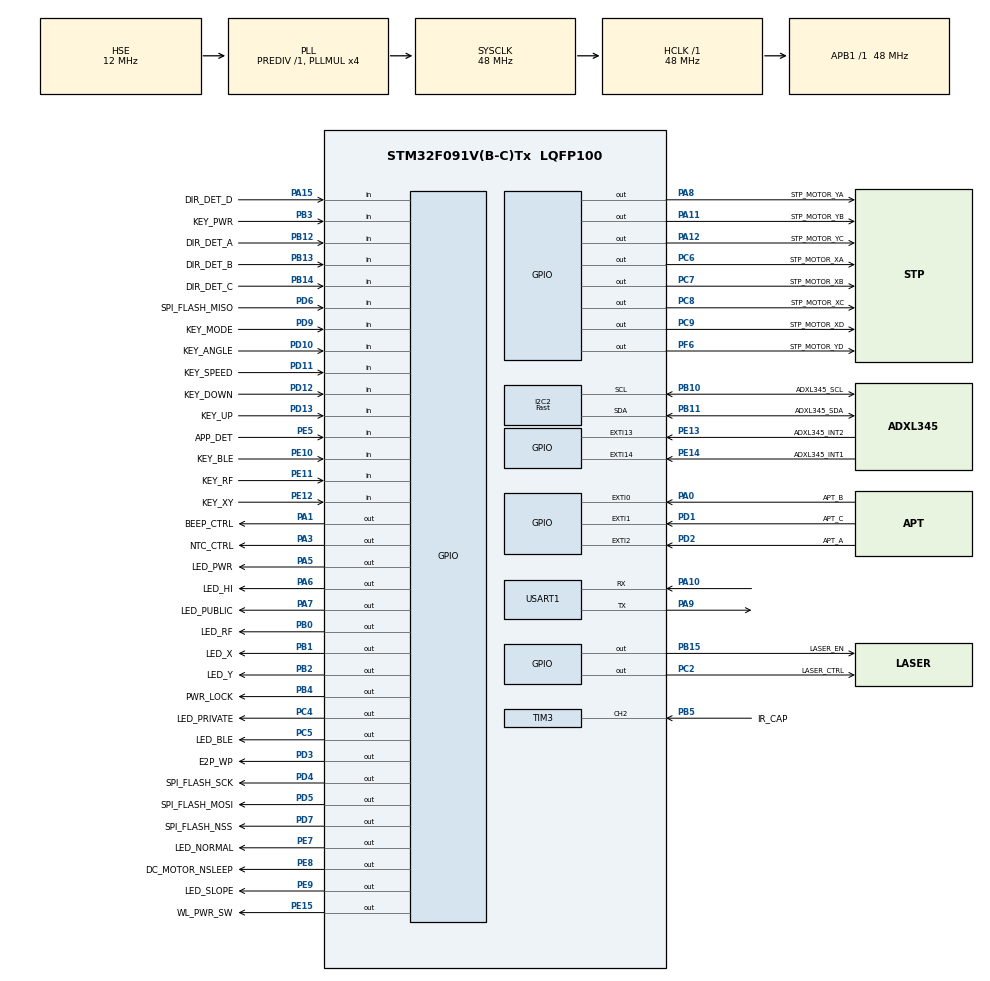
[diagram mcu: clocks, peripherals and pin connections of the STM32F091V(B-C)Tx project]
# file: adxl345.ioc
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I2C2.I2C_Speed_Mode=I2C_Fast
I2C2.Timing=0x2010091A
Mcu.Family=STM32F0
Mcu.Name=STM32F091V(B-C)Tx
Mcu.Package=LQFP100
NVIC.EXTI4_15_IRQn=true\:0\:0\:false\:false\:true\:true
NVIC.USART1_IRQn=true\:0\:0\:false\:false\:true\:true
PA0.GPIO_Label=APT_B
PA0.GPIO_ModeDefaultEXTI=GPIO_MODE_IT_RISING_FALLING
PA0.Signal=GPXTI0
PA1.GPIO_Label=BEEP_CTRL
PA1.Signal=GPIO_Output
PA10.GPIO_PuPd=GPIO_PULLUP
PA10.Mode=Asynchronous
PA10.Signal=USART1_RX
PA11.GPIO_Label=STP_MOTOR_YB
PA11.Signal=GPIO_Output
PA12.GPIO_Label=STP_MOTOR_YC
PA12.Signal=GPIO_Output
PA13.Mode=Serial_Wire
PA13.Signal=SYS_SWDIO
PA14.Mode=Serial_Wire
PA14.Signal=SYS_SWCLK
PA15.GPIO_Label=DIR_DET_D
PA15.Signal=GPIO_Input
PA3.GPIO_Label=NTC_CTRL
PA3.Signal=GPIO_Output
PA5.GPIO_Label=LED_PWR
PA5.Signal=GPIO_Output
PA6.GPIO_Label=LED_HI
PA6.Signal=GPIO_Output
PA7.GPIO_Label=LED_PUBLIC
PA7.Signal=GPIO_Output
PA8.GPIO_Label=STP_MOTOR_YA
PA8.Signal=GPIO_Output
PA9.GPIO_PuPd=GPIO_PULLUP
PA9.Mode=Asynchronous
PA9.Signal=USART1_TX
PB0.GPIO_Label=LED_RF
PB0.Signal=GPIO_Output
PB1.GPIO_Label=LED_X
PB1.Signal=GPIO_Output
PB10.GPIO_Label=ADXL345_SCL
PB10.Mode=I2C
PB10.Signal=I2C2_SCL
PB11.GPIO_Label=ADXL345_SDA
PB11.Mode=I2C
PB11.Signal=I2C2_SDA
PB12.GPIO_Label=DIR_DET_A
PB12.Signal=GPIO_Input
PB13.GPIO_Label=DIR_DET_B
PB13.Signal=GPIO_Input
PB14.GPIO_Label=DIR_DET_C
PB14.Signal=GPIO_Input
PB15.GPIO_Label=LASER_EN
PB15.Signal=GPIO_Output
PB2.GPIO_Label=LED_Y
PB2.Signal=GPIO_Output
PB3.GPIO_Label=KEY_PWR
PB3.Signal=GPIO_Input
PB4.GPIO_Label=PWR_LOCK
PB4.PinState=GPIO_PIN_SET
PB4.Signal=GPIO_Output
PB5.GPIO_Label=IR_CAP
PB5.Signal=S_TIM3_CH2
PC2.GPIO_Label=LASER_CTRL
PC2.Signal=GPIO_Output
PC4.GPIO_Label=LED_PRIVATE
PC4.Signal=GPIO_Output
PC5.GPIO_Label=LED_BLE
PC5.Signal=GPIO_Output
PC6.GPIO_Label=STP_MOTOR_XA
PC6.Signal=GPIO_Output
PC7.GPIO_Label=STP_MOTOR_XB
PC7.Signal=GPIO_Output
PC8.GPIO_Label=STP_MOTOR_XC
PC8.Signal=GPIO_Output
PC9.GPIO_Label=STP_MOTOR_XD
PC9.Signal=GPIO_Output
PD1.GPIO_Label=APT_C
PD1.GPIO_ModeDefaultEXTI=GPIO_MODE_IT_RISING_FALLING
PD1.Signal=GPXTI1
PD10.GPIO_Label=KEY_ANGLE
PD10.Signal=GPIO_Input
PD11.GPIO_Label=KEY_SPEED
PD11.Signal=GPIO_Input
PD12.GPIO_Label=KEY_DOWN
PD12.Signal=GPIO_Input
PD13.GPIO_Label=KEY_UP
PD13.Signal=GPIO_Input
PD2.GPIO_Label=APT_A
PD2.GPIO_ModeDefaultEXTI=GPIO_MODE_IT_RISING_FALLING
PD2.Signal=GPXTI2
PD3.GPIO_Label=E2P_WP
PD3.PinState=GPIO_PIN_SET
PD3.Signal=GPIO_Output
PD4.GPIO_Label=SPI_FLASH_SCK
PD4.GPIO_Speed=GPIO_SPEED_FREQ_HIGH
PD4.PinState=GPIO_PIN_SET
PD4.Signal=GPIO_Output
PD5.GPIO_Label=SPI_FLASH_MOSI
PD5.GPIO_Speed=GPIO_SPEED_FREQ_HIGH
PD5.Signal=GPIO_Output
PD6.GPIO_Label=SPI_FLASH_MISO
PD6.GPIO_PuPd=GPIO_PULLUP
PD6.Signal=GPIO_Input
PD7.GPIO_Label=SPI_FLASH_NSS
PD7.GPIO_Speed=GPIO_SPEED_FREQ_HIGH
PD7.PinState=GPIO_PIN_SET
PD7.Signal=GPIO_Output
PD9.GPIO_Label=KEY_MODE
PD9.Signal=GPIO_Input
PE10.GPIO_Label=KEY_BLE
PE10.Signal=GPIO_Input
PE11.GPIO_Label=KEY_RF
PE11.Signal=GPIO_Input
PE12.GPIO_Label=KEY_XY
PE12.Signal=GPIO_Input
PE13.GPIO_Label=ADXL345_INT2
PE13.Signal=GPXTI13
PE14.GPIO_Label=ADXL345_INT1
PE14.Signal=GPXTI14
PE15.GPIO_Label=WL_PWR_SW
PE15.Signal=GPIO_Output
PE5.GPIO_Label=APP_DET
PE5.Signal=GPIO_Input
PE7.GPIO_Label=LED_NORMAL
PE7.Signal=GPIO_Output
PE8.GPIO_Label=DC_MOTOR_NSLEEP
PE8.Signal=GPIO_Output
PE9.GPIO_Label=LED_SLOPE
PE9.Signal=GPIO_Output
PF0-OSC_IN.Mode=HSE-External-Oscillator
PF0-OSC_IN.Signal=RCC_OSC_IN
PF1-OSC_OUT.Mode=HSE-External-Oscillator
PF1-OSC_OUT.Signal=RCC_OSC_OUT
PF6.GPIO_Label=STP_MOTOR_YD
PF6.Signal=GPIO_Output
ProjectManager.HeapSize=0x1000
ProjectManager.StackSize=0x800
ProjectManager.TargetToolchain=MDK-ARM V5
RCC.AHBFreq_Value=48000000
RCC.APB1Freq_Value=48000000
RCC.APB1TimFreq_Value=48000000
RCC.HCLKFreq_Value=48000000
RCC.HSE_VALUE=12000000
RCC.I2c1ClockSelection=RCC_I2C1CLKSOURCE_HSI
RCC.PLLMUL=RCC_PLL_MUL4
RCC.PLLSourceVirtual=RCC_PLLSOURCE_HSE
RCC.SYSCLKFreq_VALUE=48000000
RCC.SYSCLKSource=RCC_SYSCLKSOURCE_PLLCLK
SH.S_TIM3_CH2.0=TIM3_CH2,Input_Capture2_from_TI2
TIM2.AutoReloadPreload=TIM_AUTORELOAD_PRELOAD_ENABLE
TIM2.Period=8000
TIM2.Prescaler=299
TIM3.AutoReloadPreload=TIM_AUTORELOAD_PRELOAD_ENABLE
TIM3.Channel-Input_Capture2_from_TI2=TIM_CHANNEL_2
TIM3.ICPolarity_CH2=TIM_INPUTCHANNELPOLARITY_BOTHEDGE
TIM3.Period=4000
TIM3.Prescaler=19
USART1.VirtualMode-Asynchronous=VM_ASYNC
USART1.WordLength=WORDLENGTH_8B
VP_TIM2_VS_ClockSourceINT.Mode=Internal
VP_TIM3_VS_ClockSourceINT.Mode=Internal
board=adxl345

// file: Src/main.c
/**
  ******************************************************************************
  * @file           : main.c
  * @brief          : Main program body
  ******************************************************************************
  ** This notice applies to any and all portions of this file
  * that are not between comment pairs USER CODE BEGIN and
  * USER CODE END. Other portions of this file, whether
  * inserted by the user or by software development tools
  * are owned by their respective copyright owners.
  *
  * COPYRIGHT(c) 2018 STMicroelectronics
  *
  * Redistribution and use in source and binary forms, with or without modification,
  * are permitted provided that the following conditions are met:
  *   1. Redistributions of source code must retain the above copyright notice,
  *      this list of conditions and the following disclaimer.
  *   2. Redistributions in binary form must reproduce the above copyright notice,
  *      this list of conditions and the following disclaimer in the documentation
  *      and/or other materials provided with the distribution.
  *   3. Neither the name of STMicroelectronics nor the names of its contributors
  *      may be used to endorse or promote products derived from this software
  *      without specific prior written permission.
  *
  * THIS SOFTWARE IS PROVIDED BY THE COPYRIGHT HOLDERS AND CONTRIBUTORS "AS IS"
  * AND ANY EXPRESS OR IMPLIED WARRANTIES, INCLUDING, BUT NOT LIMITED TO, THE
  * IMPLIED WARRANTIES OF MERCHANTABILITY AND FITNESS FOR A PARTICULAR PURPOSE ARE
  * DISCLAIMED. IN NO EVENT SHALL THE COPYRIGHT HOLDER OR CONTRIBUTORS BE LIABLE
  * FOR ANY DIRECT, INDIRECT, INCIDENTAL, SPECIAL, EXEMPLARY, OR CONSEQUENTIAL
  * DAMAGES (INCLUDING, BUT NOT LIMITED TO, PROCUREMENT OF SUBSTITUTE GOODS OR
  * SERVICES; LOSS OF USE, DATA, OR PROFITS; OR BUSINESS INTERRUPTION) HOWEVER
  * CAUSED AND ON ANY THEORY OF LIABILITY, WHETHER IN CONTRACT, STRICT LIABILITY,
  * OR TORT (INCLUDING NEGLIGENCE OR OTHERWISE) ARISING IN ANY WAY OUT OF THE USE
  * OF THIS SOFTWARE, EVEN IF ADVISED OF THE POSSIBILITY OF SUCH DAMAGE.
  *
  ******************************************************************************
  */
#include "main.h"
#include "stm32f0xx_hal.h"

/* USER CODE BEGIN Includes */

#include "ADXL345.h"
/* USER CODE END Includes */

I2C_HandleTypeDef hi2c2;

TIM_HandleTypeDef htim2;
TIM_HandleTypeDef htim3;

UART_HandleTypeDef huart1;

/* USER CODE BEGIN PV */
/* Private variables ---------------------------------------------------------*/

/* USER CODE END PV */

void SystemClock_Config(void);
static void MX_GPIO_Init(void);
static void MX_I2C2_Init(void);
static void MX_USART1_UART_Init(void);
static void MX_TIM3_Init(void);
static void MX_TIM2_Init(void);

/* USER CODE BEGIN PFP */
/* Private function prototypes -----------------------------------------------*/

/* USER CODE END PFP */

/* USER CODE BEGIN 0 */

void stdout_putchar(unsigned char c)
{
	HAL_UART_Transmit(&huart1, (uint8_t* )(&c), 1, 1000) ;
}
/* USER CODE END 0 */

int main(void)
{
  /* USER CODE BEGIN 1 */
  int loop_counter = 0 ;
  volatile int16_t x = 0 ;

  volatile int16_t y = 0 ;

  volatile int16_t z = 0 ;
  /* USER CODE END 1 */

  /* MCU Configuration----------------------------------------------------------*/

  /* Reset of all peripherals, Initializes the Flash interface and the Systick. */
  HAL_Init();

  /* Configure the system clock */
  SystemClock_Config();

  /* Initialize all configured peripherals */
  MX_GPIO_Init();
  MX_I2C2_Init();
  MX_USART1_UART_Init();
  MX_TIM3_Init();
  MX_TIM2_Init();
  /* USER CODE BEGIN 2 */

  LOCK_MAIN_POWER ;

  ADXL345_Init() ;

  /* USER CODE END 2 */

  /* Infinite loop */
  while (1)
  {

  /* USER CODE BEGIN 3 */
    if(loop_counter % 100 == 0)
    {
      TOGGLE_POWER_LED ;
      ADXL345_GetXyz(&x, &y, &z) ;
    }
    if(loop_counter++ > 10000) loop_counter = 0 ;
  }
  /* USER CODE END 3 */

}

void SystemClock_Config(void)
{

  RCC_OscInitTypeDef RCC_OscInitStruct;
  RCC_ClkInitTypeDef RCC_ClkInitStruct;
  RCC_PeriphCLKInitTypeDef PeriphClkInit;

    /**Initializes the CPU, AHB and APB busses clocks
    */
  RCC_OscInitStruct.OscillatorType = RCC_OSCILLATORTYPE_HSE;
  RCC_OscInitStruct.HSEState = RCC_HSE_ON;
  RCC_OscInitStruct.PLL.PLLState = RCC_PLL_ON;
  RCC_OscInitStruct.PLL.PLLSource = RCC_PLLSOURCE_HSE;
  RCC_OscInitStruct.PLL.PLLMUL = RCC_PLL_MUL4;
  RCC_OscInitStruct.PLL.PREDIV = RCC_PREDIV_DIV1;
  if (HAL_RCC_OscConfig(&RCC_OscInitStruct) != HAL_OK)
  {
    _Error_Handler(__FILE__, __LINE__);
  }

    /**Initializes the CPU, AHB and APB busses clocks
    */
  RCC_ClkInitStruct.ClockType = RCC_CLOCKTYPE_HCLK|RCC_CLOCKTYPE_SYSCLK
                              |RCC_CLOCKTYPE_PCLK1;
  RCC_ClkInitStruct.SYSCLKSource = RCC_SYSCLKSOURCE_PLLCLK;
  RCC_ClkInitStruct.AHBCLKDivider = RCC_SYSCLK_DIV1;
  RCC_ClkInitStruct.APB1CLKDivider = RCC_HCLK_DIV1;

  if (HAL_RCC_ClockConfig(&RCC_ClkInitStruct, FLASH_LATENCY_1) != HAL_OK)
  {
    _Error_Handler(__FILE__, __LINE__);
  }

  PeriphClkInit.PeriphClockSelection = RCC_PERIPHCLK_USART1;
  PeriphClkInit.Usart1ClockSelection = RCC_USART1CLKSOURCE_PCLK1;
  if (HAL_RCCEx_PeriphCLKConfig(&PeriphClkInit) != HAL_OK)
  {
    _Error_Handler(__FILE__, __LINE__);
  }

    /**Configure the Systick interrupt time
    */
  HAL_SYSTICK_Config(HAL_RCC_GetHCLKFreq()/1000);

    /**Configure the Systick
    */
  HAL_SYSTICK_CLKSourceConfig(SYSTICK_CLKSOURCE_HCLK);

  /* SysTick_IRQn interrupt configuration */
  HAL_NVIC_SetPriority(SysTick_IRQn, 0, 0);
}

/* I2C2 init function */
static void MX_I2C2_Init(void)
{

  hi2c2.Instance = I2C2;
  hi2c2.Init.Timing = 0x2010091A;
  hi2c2.Init.OwnAddress1 = 0;
  hi2c2.Init.AddressingMode = I2C_ADDRESSINGMODE_7BIT;
  hi2c2.Init.DualAddressMode = I2C_DUALADDRESS_DISABLE;
  hi2c2.Init.OwnAddress2 = 0;
  hi2c2.Init.OwnAddress2Masks = I2C_OA2_NOMASK;
  hi2c2.Init.GeneralCallMode = I2C_GENERALCALL_DISABLE;
  hi2c2.Init.NoStretchMode = I2C_NOSTRETCH_DISABLE;
  if (HAL_I2C_Init(&hi2c2) != HAL_OK)
  {
    _Error_Handler(__FILE__, __LINE__);
  }

    /**Configure Analogue filter
    */
  if (HAL_I2CEx_ConfigAnalogFilter(&hi2c2, I2C_ANALOGFILTER_ENABLE) != HAL_OK)
  {
    _Error_Handler(__FILE__, __LINE__);
  }

    /**Configure Digital filter
    */
  if (HAL_I2CEx_ConfigDigitalFilter(&hi2c2, 0) != HAL_OK)
  {
    _Error_Handler(__FILE__, __LINE__);
  }

}

/* TIM2 init function */
static void MX_TIM2_Init(void)
{

  TIM_ClockConfigTypeDef sClockSourceConfig;
  TIM_MasterConfigTypeDef sMasterConfig;

  htim2.Instance = TIM2;
  htim2.Init.Prescaler = 299;
  htim2.Init.CounterMode = TIM_COUNTERMODE_UP;
  htim2.Init.Period = 8000;
  htim2.Init.ClockDivision = TIM_CLOCKDIVISION_DIV1;
  htim2.Init.AutoReloadPreload = TIM_AUTORELOAD_PRELOAD_ENABLE;
  if (HAL_TIM_Base_Init(&htim2) != HAL_OK)
  {
    _Error_Handler(__FILE__, __LINE__);
  }

  sClockSourceConfig.ClockSource = TIM_CLOCKSOURCE_INTERNAL;
  if (HAL_TIM_ConfigClockSource(&htim2, &sClockSourceConfig) != HAL_OK)
  {
    _Error_Handler(__FILE__, __LINE__);
  }

  sMasterConfig.MasterOutputTrigger = TIM_TRGO_RESET;
  sMasterConfig.MasterSlaveMode = TIM_MASTERSLAVEMODE_DISABLE;
  if (HAL_TIMEx_MasterConfigSynchronization(&htim2, &sMasterConfig) != HAL_OK)
  {
    _Error_Handler(__FILE__, __LINE__);
  }

}

/* TIM3 init function */
static void MX_TIM3_Init(void)
{

  TIM_ClockConfigTypeDef sClockSourceConfig;
  TIM_MasterConfigTypeDef sMasterConfig;
  TIM_IC_InitTypeDef sConfigIC;

  htim3.Instance = TIM3;
  htim3.Init.Prescaler = 19;
  htim3.Init.CounterMode = TIM_COUNTERMODE_UP;
  htim3.Init.Period = 4000;
  htim3.Init.ClockDivision = TIM_CLOCKDIVISION_DIV1;
  htim3.Init.AutoReloadPreload = TIM_AUTORELOAD_PRELOAD_ENABLE;
  if (HAL_TIM_Base_Init(&htim3) != HAL_OK)
  {
    _Error_Handler(__FILE__, __LINE__);
  }

  sClockSourceConfig.ClockSource = TIM_CLOCKSOURCE_INTERNAL;
  if (HAL_TIM_ConfigClockSource(&htim3, &sClockSourceConfig) != HAL_OK)
  {
    _Error_Handler(__FILE__, __LINE__);
  }

  if (HAL_TIM_IC_Init(&htim3) != HAL_OK)
  {
    _Error_Handler(__FILE__, __LINE__);
  }

  sMasterConfig.MasterOutputTrigger = TIM_TRGO_RESET;
  sMasterConfig.MasterSlaveMode = TIM_MASTERSLAVEMODE_DISABLE;
  if (HAL_TIMEx_MasterConfigSynchronization(&htim3, &sMasterConfig) != HAL_OK)
  {
    _Error_Handler(__FILE__, __LINE__);
  }

  sConfigIC.ICPolarity = TIM_INPUTCHANNELPOLARITY_BOTHEDGE;
  sConfigIC.ICSelection = TIM_ICSELECTION_DIRECTTI;
  sConfigIC.ICPrescaler = TIM_ICPSC_DIV1;
  sConfigIC.ICFilter = 0;
  if (HAL_TIM_IC_ConfigChannel(&htim3, &sConfigIC, TIM_CHANNEL_2) != HAL_OK)
  {
    _Error_Handler(__FILE__, __LINE__);
  }

}

/* USART1 init function */
static void MX_USART1_UART_Init(void)
{

  huart1.Instance = USART1;
  huart1.Init.BaudRate = 115200;
  huart1.Init.WordLength = UART_WORDLENGTH_8B;
  huart1.Init.StopBits = UART_STOPBITS_1;
  huart1.Init.Parity = UART_PARITY_NONE;
  huart1.Init.Mode = UART_MODE_TX_RX;
  huart1.Init.HwFlowCtl = UART_HWCONTROL_NONE;
  huart1.Init.OverSampling = UART_OVERSAMPLING_16;
  huart1.Init.OneBitSampling = UART_ONE_BIT_SAMPLE_DISABLE;
  huart1.AdvancedInit.AdvFeatureInit = UART_ADVFEATURE_NO_INIT;
  if (HAL_UART_Init(&huart1) != HAL_OK)
  {
    _Error_Handler(__FILE__, __LINE__);
  }

}

/** Configure pins as
        * Analog
        * Input
        * Output
        * EVENT_OUT
        * EXTI
*/
static void MX_GPIO_Init(void)
{

  GPIO_InitTypeDef GPIO_InitStruct;

  /* GPIO Ports Clock Enable */
  __HAL_RCC_GPIOE_CLK_ENABLE();
  __HAL_RCC_GPIOF_CLK_ENABLE();
  __HAL_RCC_GPIOC_CLK_ENABLE();
  __HAL_RCC_GPIOA_CLK_ENABLE();
  __HAL_RCC_GPIOB_CLK_ENABLE();
  __HAL_RCC_GPIOD_CLK_ENABLE();

  /*Configure GPIO pin Output Level */
  HAL_GPIO_WritePin(GPIOC, LASER_CTRL_Pin|LED_PRIVATE_Pin|LED_BLE_Pin|STP_MOTOR_XA_Pin
                          |STP_MOTOR_XB_Pin|STP_MOTOR_XC_Pin|STP_MOTOR_XD_Pin, GPIO_PIN_RESET);

  /*Configure GPIO pin Output Level */
  HAL_GPIO_WritePin(GPIOA, BEEP_CTRL_Pin|NTC_CTRL_Pin|LED_PWR_Pin|LED_HI_Pin
                          |LED_PUBLIC_Pin|STP_MOTOR_YA_Pin|STP_MOTOR_YB_Pin|STP_MOTOR_YC_Pin, GPIO_PIN_RESET);

  /*Configure GPIO pin Output Level */
  HAL_GPIO_WritePin(GPIOB, LED_RF_Pin|LED_X_Pin|LED_Y_Pin|LASER_EN_Pin, GPIO_PIN_RESET);

  /*Configure GPIO pin Output Level */
  HAL_GPIO_WritePin(GPIOE, LED_NORMAL_Pin|DC_MOTOR_NSLEEP_Pin|LED_SLOPE_Pin|WL_PWR_SW_Pin, GPIO_PIN_RESET);

  /*Configure GPIO pin Output Level */
  HAL_GPIO_WritePin(STP_MOTOR_YD_GPIO_Port, STP_MOTOR_YD_Pin, GPIO_PIN_RESET);

  /*Configure GPIO pin Output Level */
  HAL_GPIO_WritePin(GPIOD, E2P_WP_Pin|SPI_FLASH_SCK_Pin|SPI_FLASH_NSS_Pin, GPIO_PIN_SET);

  /*Configure GPIO pin Output Level */
  HAL_GPIO_WritePin(SPI_FLASH_MOSI_GPIO_Port, SPI_FLASH_MOSI_Pin, GPIO_PIN_RESET);

  /*Configure GPIO pin Output Level */
  HAL_GPIO_WritePin(PWR_LOCK_GPIO_Port, PWR_LOCK_Pin, GPIO_PIN_SET);

  /*Configure GPIO pins : APP_DET_Pin KEY_BLE_Pin KEY_RF_Pin KEY_XY_Pin */
  GPIO_InitStruct.Pin = APP_DET_Pin|KEY_BLE_Pin|KEY_RF_Pin|KEY_XY_Pin;
  GPIO_InitStruct.Mode = GPIO_MODE_INPUT;
  GPIO_InitStruct.Pull = GPIO_NOPULL;
  HAL_GPIO_Init(GPIOE, &GPIO_InitStruct);

  /*Configure GPIO pins : LASER_CTRL_Pin LED_PRIVATE_Pin LED_BLE_Pin STP_MOTOR_XA_Pin
                           STP_MOTOR_XB_Pin STP_MOTOR_XC_Pin STP_MOTOR_XD_Pin */
  GPIO_InitStruct.Pin = LASER_CTRL_Pin|LED_PRIVATE_Pin|LED_BLE_Pin|STP_MOTOR_XA_Pin
                          |STP_MOTOR_XB_Pin|STP_MOTOR_XC_Pin|STP_MOTOR_XD_Pin;
  GPIO_InitStruct.Mode = GPIO_MODE_OUTPUT_PP;
  GPIO_InitStruct.Pull = GPIO_NOPULL;
  GPIO_InitStruct.Speed = GPIO_SPEED_FREQ_LOW;
  HAL_GPIO_Init(GPIOC, &GPIO_InitStruct);

  /*Configure GPIO pin : APT_B_Pin */
  GPIO_InitStruct.Pin = APT_B_Pin;
  GPIO_InitStruct.Mode = GPIO_MODE_IT_RISING_FALLING;
  GPIO_InitStruct.Pull = GPIO_NOPULL;
  HAL_GPIO_Init(APT_B_GPIO_Port, &GPIO_InitStruct);

  /*Configure GPIO pins : BEEP_CTRL_Pin NTC_CTRL_Pin LED_PWR_Pin LED_HI_Pin
                           LED_PUBLIC_Pin STP_MOTOR_YA_Pin STP_MOTOR_YB_Pin STP_MOTOR_YC_Pin */
  GPIO_InitStruct.Pin = BEEP_CTRL_Pin|NTC_CTRL_Pin|LED_PWR_Pin|LED_HI_Pin
                          |LED_PUBLIC_Pin|STP_MOTOR_YA_Pin|STP_MOTOR_YB_Pin|STP_MOTOR_YC_Pin;
  GPIO_InitStruct.Mode = GPIO_MODE_OUTPUT_PP;
  GPIO_InitStruct.Pull = GPIO_NOPULL;
  GPIO_InitStruct.Speed = GPIO_SPEED_FREQ_LOW;
  HAL_GPIO_Init(GPIOA, &GPIO_InitStruct);

  /*Configure GPIO pins : LED_RF_Pin LED_X_Pin LED_Y_Pin LASER_EN_Pin
                           PWR_LOCK_Pin */
  GPIO_InitStruct.Pin = LED_RF_Pin|LED_X_Pin|LED_Y_Pin|LASER_EN_Pin
                          |PWR_LOCK_Pin;
  GPIO_InitStruct.Mode = GPIO_MODE_OUTPUT_PP;
  GPIO_InitStruct.Pull = GPIO_NOPULL;
  GPIO_InitStruct.Speed = GPIO_SPEED_FREQ_LOW;
  HAL_GPIO_Init(GPIOB, &GPIO_InitStruct);

  /*Configure GPIO pins : LED_NORMAL_Pin DC_MOTOR_NSLEEP_Pin LED_SLOPE_Pin WL_PWR_SW_Pin */
  GPIO_InitStruct.Pin = LED_NORMAL_Pin|DC_MOTOR_NSLEEP_Pin|LED_SLOPE_Pin|WL_PWR_SW_Pin;
  GPIO_InitStruct.Mode = GPIO_MODE_OUTPUT_PP;
  GPIO_InitStruct.Pull = GPIO_NOPULL;
  GPIO_InitStruct.Speed = GPIO_SPEED_FREQ_LOW;
  HAL_GPIO_Init(GPIOE, &GPIO_InitStruct);

  /*Configure GPIO pins : ADXL345_INT2_Pin ADXL345_INT1_Pin */
  GPIO_InitStruct.Pin = ADXL345_INT2_Pin|ADXL345_INT1_Pin;
  GPIO_InitStruct.Mode = GPIO_MODE_IT_RISING;
  GPIO_InitStruct.Pull = GPIO_NOPULL;
  HAL_GPIO_Init(GPIOE, &GPIO_InitStruct);

  /*Configure GPIO pins : DIR_DET_A_Pin DIR_DET_B_Pin DIR_DET_C_Pin KEY_PWR_Pin */
  GPIO_InitStruct.Pin = DIR_DET_A_Pin|DIR_DET_B_Pin|DIR_DET_C_Pin|KEY_PWR_Pin;
  GPIO_InitStruct.Mode = GPIO_MODE_INPUT;
  GPIO_InitStruct.Pull = GPIO_NOPULL;
  HAL_GPIO_Init(GPIOB, &GPIO_InitStruct);

  /*Configure GPIO pins : KEY_MODE_Pin KEY_ANGLE_Pin KEY_SPEED_Pin KEY_DOWN_Pin
                           KEY_UP_Pin */
  GPIO_InitStruct.Pin = KEY_MODE_Pin|KEY_ANGLE_Pin|KEY_SPEED_Pin|KEY_DOWN_Pin
                          |KEY_UP_Pin;
  GPIO_InitStruct.Mode = GPIO_MODE_INPUT;
  GPIO_InitStruct.Pull = GPIO_NOPULL;
  HAL_GPIO_Init(GPIOD, &GPIO_InitStruct);

  /*Configure GPIO pin : STP_MOTOR_YD_Pin */
  GPIO_InitStruct.Pin = STP_MOTOR_YD_Pin;
  GPIO_InitStruct.Mode = GPIO_MODE_OUTPUT_PP;
  GPIO_InitStruct.Pull = GPIO_NOPULL;
  GPIO_InitStruct.Speed = GPIO_SPEED_FREQ_LOW;
  HAL_GPIO_Init(STP_MOTOR_YD_GPIO_Port, &GPIO_InitStruct);

  /*Configure GPIO pin : DIR_DET_D_Pin */
  GPIO_InitStruct.Pin = DIR_DET_D_Pin;
  GPIO_InitStruct.Mode = GPIO_MODE_INPUT;
  GPIO_InitStruct.Pull = GPIO_NOPULL;
  HAL_GPIO_Init(DIR_DET_D_GPIO_Port, &GPIO_InitStruct);

  /*Configure GPIO pins : APT_C_Pin APT_A_Pin */
  GPIO_InitStruct.Pin = APT_C_Pin|APT_A_Pin;
  GPIO_InitStruct.Mode = GPIO_MODE_IT_RISING_FALLING;
  GPIO_InitStruct.Pull = GPIO_NOPULL;
  HAL_GPIO_Init(GPIOD, &GPIO_InitStruct);

  /*Configure GPIO pin : E2P_WP_Pin */
  GPIO_InitStruct.Pin = E2P_WP_Pin;
  GPIO_InitStruct.Mode = GPIO_MODE_OUTPUT_PP;
  GPIO_InitStruct.Pull = GPIO_NOPULL;
  GPIO_InitStruct.Speed = GPIO_SPEED_FREQ_LOW;
  HAL_GPIO_Init(E2P_WP_GPIO_Port, &GPIO_InitStruct);

  /*Configure GPIO pins : SPI_FLASH_SCK_Pin SPI_FLASH_MOSI_Pin SPI_FLASH_NSS_Pin */
  GPIO_InitStruct.Pin = SPI_FLASH_SCK_Pin|SPI_FLASH_MOSI_Pin|SPI_FLASH_NSS_Pin;
  GPIO_InitStruct.Mode = GPIO_MODE_OUTPUT_PP;
  GPIO_InitStruct.Pull = GPIO_NOPULL;
  GPIO_InitStruct.Speed = GPIO_SPEED_FREQ_HIGH;
  HAL_GPIO_Init(GPIOD, &GPIO_InitStruct);

  /*Configure GPIO pin : SPI_FLASH_MISO_Pin */
  GPIO_InitStruct.Pin = SPI_FLASH_MISO_Pin;
  GPIO_InitStruct.Mode = GPIO_MODE_INPUT;
  GPIO_InitStruct.Pull = GPIO_PULLUP;
  HAL_GPIO_Init(SPI_FLASH_MISO_GPIO_Port, &GPIO_InitStruct);

  /* EXTI interrupt init*/
  HAL_NVIC_SetPriority(EXTI4_15_IRQn, 0, 0);
  HAL_NVIC_EnableIRQ(EXTI4_15_IRQn);

}

void _Error_Handler(char *file, int line)
{
  while(1)
  {
  }
}

#ifdef  USE_FULL_ASSERT
/**
  * @brief  Reports the name of the source file and the source line number
  *         where the assert_param error has occurred.
  * @param  file: pointer to the source file name
  * @param  line: assert_param error line source number
  * @retval None
  */
void assert_failed(uint8_t* file, uint32_t line)
{
  /* USER CODE BEGIN 6 */
  /* User can add his own implementation to report the file name and line number,
     tex: printf("Wrong parameters value: file %s on line %d\r\n", file, line) */

  printf("Wrong parameters value: file %s on line %d\r\n", file, line) ;
  /* USER CODE END 6 */
}
#endif /* USE_FULL_ASSERT */

/************************ (C) COPYRIGHT STMicroelectronics *****END OF FILE****/
